VERSION ""

NS_ :

BS_:

BU_: K182_PACM K43_PSCM K17_EBCM NEO K124_ASCM

BO_ 821 APASteerStatus: 4 K43_PSCM
 SG_ Request_Valid : 0|1@0+ (1,0) [0|1] "" K182_PACM
 SG_ Steer_Active : 1|1@0+ (1,0) [0|1] "" K182_PACM

BO_ 485 PSCMSteeringAngle: 8 K43_PSCM
  SG_ Angle : 15|16@0- (0.0625,0) [0|0] "º"  K182_PACM

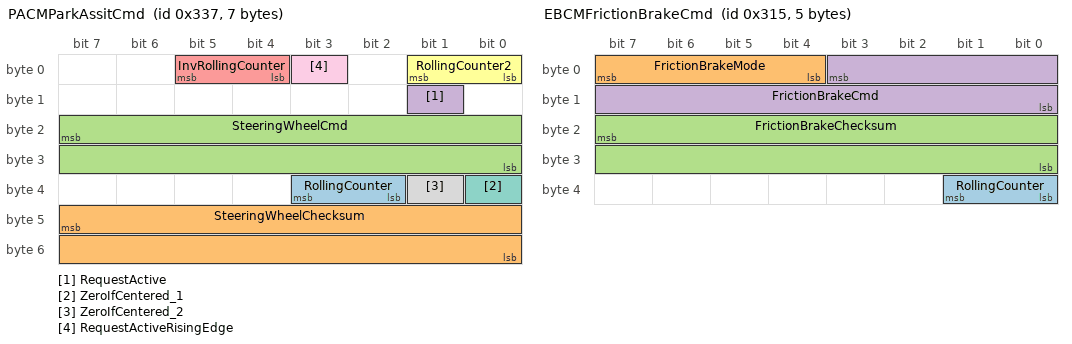
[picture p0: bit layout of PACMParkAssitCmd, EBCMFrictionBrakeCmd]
BO_ 823 PACMParkAssitCmd: 7 NEO
 SG_ RollingCounter : 35|2@0+ (1,0) [0|0] ""  NEO
 SG_ SteeringWheelChecksum : 47|16@0+ (1,0) [0|0] ""  NEO
 SG_ SteeringWheelCmd : 23|16@0- (0.0625,0) [0|0] "º"  NEO
 SG_ RequestActive : 9|1@0+ (1,0) [0|1] "" XXX
 SG_ InvRollingCounter : 5|2@0+ (1,0) [0|1] "" XXX
 SG_ RollingCounter2 : 1|2@0+ (1,0) [0|1] "" XXX
 SG_ ZeroIfCentered_1 : 32|1@0+ (1,0) [0|1] "" XXX
 SG_ ZeroIfCentered_2 : 33|1@0+ (1,0) [0|1] "" XXX
 SG_ RequestActiveRisingEdge : 3|1@0+ (1,0) [0|1] "" XXX

BO_ 560 EBCMRegen: 6 K17_EBCM
 SG_ Regen : 1|10@0+ (1,0) [0|0] ""  NEO

BO_ 368 EBCMFrictionBrakeStatus: 8 K17_EBCM
 SG_ FrictionBrakePressure : 23|16@0+ (1,0) [0|0] ""  NEO

BO_ 789 EBCMFrictionBrakeCmd: 5 K17_EBCM
 SG_ RollingCounter : 33|2@0+ (1,0) [0|0] ""  NEO
 SG_ FrictionBrakeMode : 7|4@0+ (1,0) [0|0] ""  NEO
 SG_ FrictionBrakeChecksum : 23|16@0+ (1,0) [0|0] ""  NEO
 SG_ FrictionBrakeCmd : 3|12@0- (1,0) [0|0] ""  NEO

BO_TX_BU_ 823 : K43_PSCM,NEO;
BO_TX_BU_ 789 : NEO,K17_EBCM;

CM_ BU_ K182_PACM "Parking Assist Control Module";
CM_ BU_ K43_PSCM "Power Steering Control Module";
CM_ BU_ K17_EBCM "Electronic Brake Control Module";
CM_ BU_ NEO "Comma NEO";
CM_ BU_ K124_ASCM "Active Safety Control Module";
BA_DEF_  "UseGMParameterIDs" INT 0 0;
BA_DEF_  "ProtocolType" STRING ;
BA_DEF_  "BusType" STRING ;
BA_DEF_DEF_  "UseGMParameterIDs" 1;
BA_DEF_DEF_  "ProtocolType" "GMLAN";
BA_DEF_DEF_  "BusType" "";
BA_ "UseGMParameterIDs" 0;
BA_ "BusType" "CAN";
